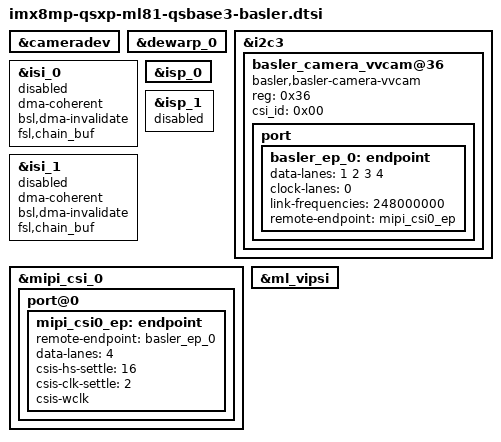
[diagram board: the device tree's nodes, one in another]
// SPDX-License-Identifier: (GPL-2.0 OR MIT)
/*
 * Copyright (C) 2020 Markus Bauer <mb@karo-electronics.de>
 *
 */

&cameradev {
	status = "okay";
};

&dewarp_0 {
	status = "okay";
};

&i2c3 {
	status = "okay";

	basler_camera_vvcam@36 {
		compatible = "basler,basler-camera-vvcam", "basler-camera-vvcam";
		reg = <0x36>;
		csi_id = <0x00>;
		status = "okay";

		port {
			basler_ep_0: endpoint {
				data-lanes = <1 2 3 4>;
				clock-lanes = <0>;
				link-frequencies = /bits/ 64 <248000000>;
				remote-endpoint = <&mipi_csi0_ep>;
			};
		};
	};
};

&isi_0 {
	dma-coherent;
	bsl,dma-invalidate;
	fsl,chain_buf;
	status = "disabled";
};

&isi_1 {
	dma-coherent;
	bsl,dma-invalidate;
	fsl,chain_buf;
	status = "disabled";
};

&isp_0 {
	status = "okay";
};

&isp_1 {
	status = "disabled";
};

&mipi_csi_0 {
	#address-cells = <1>;
	#size-cells = <0>;
	status = "okay";

	port@0 {
		mipi_csi0_ep: endpoint {
			remote-endpoint = <&basler_ep_0>;
			data-lanes = <4>;
			csis-hs-settle = <16>;
			csis-clk-settle = <2>;
			csis-wclk;
		};
	};
};

&ml_vipsi {
	status = "okay";
};
